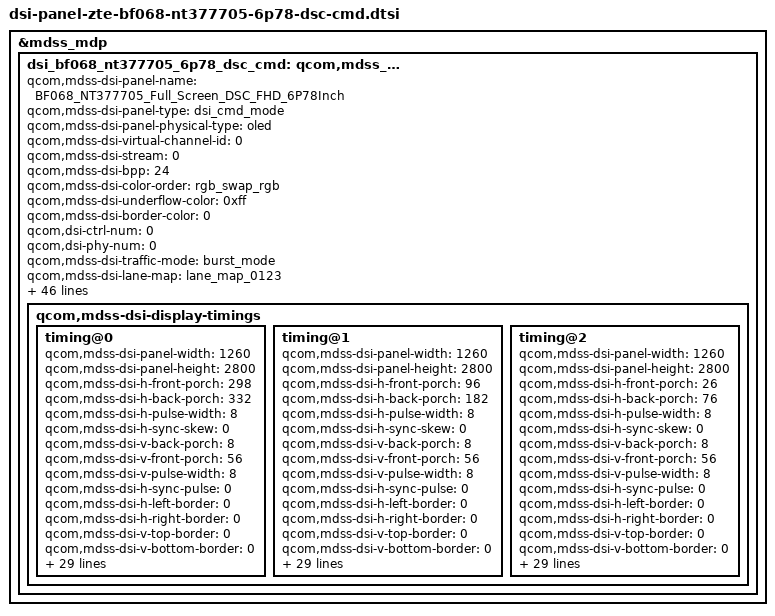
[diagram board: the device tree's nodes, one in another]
&mdss_mdp {
	dsi_bf068_nt377705_6p78_dsc_cmd: qcom,mdss_dsi_bf068_nt377705_6p78_dsc_cmd {
		qcom,mdss-dsi-panel-name =
				"BF068_NT377705_Full_Screen_DSC_FHD_6P78Inch";
		qcom,mdss-dsi-panel-type = "dsi_cmd_mode";
		qcom,mdss-dsi-panel-physical-type = "oled";
		qcom,mdss-dsi-virtual-channel-id = <0>;
		qcom,mdss-dsi-stream = <0>;
		qcom,mdss-dsi-bpp = <24>;
		qcom,mdss-dsi-color-order = "rgb_swap_rgb";
		qcom,mdss-dsi-underflow-color = <0xff>;
		qcom,mdss-dsi-border-color = <0>;
		qcom,dsi-ctrl-num = <0>;
		qcom,dsi-phy-num = <0>;
		qcom,mdss-dsi-traffic-mode = "burst_mode";
		qcom,mdss-dsi-lane-map = "lane_map_0123";
		qcom,mdss-dsi-bllp-eof-power-mode;
		qcom,mdss-dsi-bllp-power-mode;
		qcom,mdss-dsi-lane-0-state;
		qcom,mdss-dsi-lane-1-state;
		qcom,mdss-dsi-lane-2-state;
		qcom,mdss-dsi-lane-3-state;
		qcom,mdss-dsi-lp11-init;
		qcom,mdss-dsi-tx-eot-append;
		qcom,mdss-dsi-dma-trigger = "trigger_sw";
		qcom,mdss-dsi-mdp-trigger = "none";
		qcom,mdss-dsi-reset-sequence = <1 5>, <0 5>, <1 10>;
		qcom,mdss-dsi-te-pin-select = <1>;
		qcom,mdss-dsi-te-dcs-command = <1>;
		qcom,mdss-dsi-te-check-enable;
		qcom,mdss-dsi-te-using-te-pin;
		qcom,mdss-dsi-bl-min-level = <80>;
		qcom,mdss-dsi-bl-max-level = <3515>;
		qcom,mdss-dsi-bl-pmic-control-type = "bl_ctrl_dcs";
		qcom,mdss-dsi-panel-hdr-enabled;
		qcom,mdss-dsi-panel-hdr-color-primaries = <14500 15500 34015
			15980 13030 34670 6950 2565>;
		qcom,mdss-dsi-panel-peak-brightness = <6680000>;
		qcom,mdss-dsi-panel-blackness-level = <20>;
		qcom,mdss-pan-physical-width-dimension = <71>;
		qcom,mdss-pan-physical-height-dimension = <157>;
		qcom,bl-dcs-cmd-state = "dsi_lp_mode";
		qcom,mdss-dsi-display-timings {
			timing@0{
				qcom,mdss-dsi-panel-width = <1260>;
				qcom,mdss-dsi-panel-height = <2800>;
				qcom,mdss-dsi-h-front-porch = <298>;
				qcom,mdss-dsi-h-back-porch = <332>;
				qcom,mdss-dsi-h-pulse-width = <8>;
				qcom,mdss-dsi-h-sync-skew = <0>;
				qcom,mdss-dsi-v-back-porch = <8>;
				qcom,mdss-dsi-v-front-porch = <56>;
				qcom,mdss-dsi-v-pulse-width = <8>;
				qcom,mdss-dsi-h-sync-pulse = <0>;
				qcom,mdss-dsi-h-left-border = <0>;
				qcom,mdss-dsi-h-right-border = <0>;
				qcom,mdss-dsi-v-top-border = <0>;
				qcom,mdss-dsi-v-bottom-border = <0>;
				qcom,mdss-dsi-panel-framerate = <60>;
				qcom,mdss-dsi-panel-clockrate = <1093960000>;

				qcom,mdss-dsi-on-command = [
					39 01 00 00 00 00 06 F0 55 AA 52 08 00
					39 01 00 00 00 00 02 B0 0C
					39 01 00 00 00 00 02 6F 09
					39 01 00 00 00 00 04 B0 55 56 55
					39 01 00 00 00 00 04 B1 17 3B 5C
					39 01 00 00 00 00 02 6F 03
					39 01 00 00 00 00 03 B1 00 17
					39 01 00 00 00 00 02 6F 14
					39 01 00 00 00 00 03 B1 00 3B
					39 01 00 00 00 00 02 6F 16
					39 01 00 00 00 00 03 B1 00 5C
					39 01 00 00 00 00 02 6F 05
					39 01 00 00 00 00 0D B1 12 34 57 89 2C 58 84 B0 DC 08 34 60
					39 01 00 00 00 00 02 6F 21
					39 01 00 00 00 00 0F B1 00 00 24 68 AC EF 00 00 00 00 00 00 00 FF
					39 01 00 00 00 00 02 6F 18
					39 01 00 00 00 00 07 B1 02 76 04 EC 02 76
					39 01 00 00 00 00 02 6F 1E
					39 01 00 00 00 00 04 B1 0D 75 50
					39 01 00 00 00 00 02 B2 19
					39 01 00 00 00 00 02 6F 06
					39 01 00 00 00 00 07 B5 7F 4B 29 4F 00 00
					39 01 00 00 00 00 02 6F 0C
					39 01 00 00 00 00 06 B5 44 25 4F 00 00
					39 01 00 00 00 00 02 6F 11
					39 01 00 00 00 00 06 B5 29 29 29 29 29
					39 01 00 00 00 00 02 6F 18
					39 01 00 00 00 00 06 B5 00 00 00 00 00
					39 01 00 00 00 00 02 6F 1D
					39 01 00 00 00 00 06 B5 00 00 00 00 00
					39 01 00 00 00 00 02 6F 27
					39 01 00 00 00 00 06 B5 00 00 00 00 00

					39 01 00 00 00 00 06 F0 55 AA 52 08 01
					39 01 00 00 00 00 2A C3 DD 06 20 11 FF 00 06 20 11 FF 00 04 49 11 05 CC 17 04 4A 11 05 CD 17 04 4B 11 05 CF 17 04 49 11 05 CC 17 04 49 11 05 CC 17
					39 01 00 00 00 00 02 6F 05
					39 01 00 00 00 00 05 C5 15 15 15 DD
					39 01 00 00 00 00 06 F0 55 AA 52 00 00
					39 01 00 00 00 00 05 FF AA 55 A5 80
					39 01 00 00 00 00 02 6F 19
					39 01 00 00 00 00 02 F2 00
					39 01 00 00 00 00 02 6F 1A
					39 01 00 00 00 00 02 F4 55
					39 01 00 00 00 00 02 6F 2D
					39 01 00 00 00 00 02 FC 44
					39 01 00 00 00 00 02 6F 11
					39 01 00 00 00 00 03 F8 01 7B
					39 01 00 00 00 00 02 6F 2D
					39 01 00 00 00 00 03 F8 01 1D
					39 01 00 00 00 00 05 FF AA 55 A5 81
					39 01 00 00 00 00 02 6F 05
					39 01 00 00 00 00 02 FE 3C
					39 01 00 00 00 00 02 6F 02
					39 01 00 00 00 00 02 F9 04
					39 01 00 00 00 00 02 6F 1E
					39 01 00 00 00 00 02 FB 0F
					39 01 00 00 00 00 02 6F 0F
					39 01 00 00 00 00 02 F5 20
					39 01 00 00 00 00 02 6F 24
					39 01 00 00 00 00 15 FB 00 01 00 11 33 33 33 55 57 D0 00 00 44 56 77 78 9A BC DD F0

					39 01 00 00 00 00 05 FF AA 55 A5 82
					39 01 00 00 00 00 02 6F 09
					39 01 00 00 00 00 02 F2 55
					39 01 00 00 00 00 05 FF AA 55 A5 83
					39 01 00 00 00 00 02 6F 12
					39 01 00 00 00 00 02 FE 41
					39 01 00 00 00 00 02 6F 13
					39 01 00 00 00 00 02 FD 21
					39 01 00 00 00 00 05 FF AA 55 A5 00
					05 01 00 00 00 00 01 35
					39 01 00 00 00 00 02 53 20
					39 01 00 00 00 00 05 2A 00 00 04 EB
					39 01 00 00 00 00 05 2B 00 00 0A EF
					39 01 00 00 00 00 02 26 00
					39 01 00 00 00 00 03 51 0D BB
					39 01 00 00 00 00 02 6F 04
					39 01 00 00 00 00 03 51 0F FE
					39 01 00 00 00 00 03 81 01 19
					39 01 00 00 00 00 02 03 01
					39 01 00 00 00 00 03 90 03 03
					39 01 00 00 00 00 13 91 89 28 00 14 C2 00 02 3B 02 0E 00 08 05 0E 04 5C 10 F0

					39 01 00 00 00 00 06 F0 55 AA 52 08 01
					39 01 00 00 00 00 02 6F 18
					39 01 00 00 00 00 02 D8 18
					05 01 00 00 00 00 01 2C
					39 01 00 00 14 00 02 2F 02
					05 01 00 00 78 00 01 11
					05 01 00 00 00 00 01 29
					];
				qcom,mdss-dsi-off-command = [
					05 01 00 00 14 00 01 28
					05 01 00 00 78 00 01 10
				];
				qcom,mdss-dsi-on-command-state = "dsi_lp_mode";
				qcom,mdss-dsi-off-command-state = "dsi_lp_mode";

				qcom,mdss-dsi-lp1-command = [
					05 01 00 00 00 00 01 39
					05 01 00 00 00 00 01 2C
				];
				qcom,mdss-dsi-lp1-command-state =
					"dsi_lp_mode";
				qcom,mdss-dsi-nolp-command = [
					39 01 00 00 00 00 03 51 00 00
					05 01 00 00 00 00 01 38
					05 01 00 00 00 00 01 2C
				];
				qcom,mdss-dsi-nolp-command-state =
					"dsi_lp_mode";
				qcom,mdss-dsi-timing-switch-command = [
					39 01 00 00 00 00 02 2F 02
				];
				qcom,mdss-dsi-timing-switch-command-state =
					"dsi_lp_mode";
				qcom,compression-mode = "dsc";
				qcom,mdss-dsc-slice-height = <20>;
				qcom,mdss-dsc-slice-width = <630>;
				qcom,mdss-dsc-slice-per-pkt = <2>;
				qcom,mdss-dsc-bit-per-component = <8>;
				qcom,mdss-dsc-bit-per-pixel = <8>;
				qcom,mdss-dsc-block-prediction-enable;
			};
			timing@1{
				qcom,mdss-dsi-panel-width = <1260>;
				qcom,mdss-dsi-panel-height = <2800>;
				qcom,mdss-dsi-h-front-porch = <96>;
				qcom,mdss-dsi-h-back-porch = <182>;
				qcom,mdss-dsi-h-pulse-width = <8>;
				qcom,mdss-dsi-h-sync-skew = <0>;
				qcom,mdss-dsi-v-back-porch = <8>;
				qcom,mdss-dsi-v-front-porch = <56>;
				qcom,mdss-dsi-v-pulse-width = <8>;
				qcom,mdss-dsi-h-sync-pulse = <0>;
				qcom,mdss-dsi-h-left-border = <0>;
				qcom,mdss-dsi-h-right-border = <0>;
				qcom,mdss-dsi-v-top-border = <0>;
				qcom,mdss-dsi-v-bottom-border = <0>;
				qcom,mdss-dsi-panel-framerate = <90>;
				qcom,mdss-dsi-panel-clockrate = <1094960000>;

				qcom,mdss-dsi-on-command = [
					39 01 00 00 00 00 06 F0 55 AA 52 08 00
					39 01 00 00 00 00 02 B0 0C
					39 01 00 00 00 00 02 6F 09
					39 01 00 00 00 00 04 B0 55 56 55
					39 01 00 00 00 00 04 B1 17 3B 5C
					39 01 00 00 00 00 02 6F 03
					39 01 00 00 00 00 03 B1 00 17
					39 01 00 00 00 00 02 6F 14
					39 01 00 00 00 00 03 B1 00 3B
					39 01 00 00 00 00 02 6F 16
					39 01 00 00 00 00 03 B1 00 5C
					39 01 00 00 00 00 02 6F 05
					39 01 00 00 00 00 0D B1 12 34 57 89 2C 58 84 B0 DC 08 34 60
					39 01 00 00 00 00 02 6F 21
					39 01 00 00 00 00 0F B1 00 00 24 68 AC EF 00 00 00 00 00 00 00 FF
					39 01 00 00 00 00 02 6F 18
					39 01 00 00 00 00 07 B1 02 76 04 EC 02 76
					39 01 00 00 00 00 02 6F 1E
					39 01 00 00 00 00 04 B1 0D 75 50
					39 01 00 00 00 00 02 B2 19
					39 01 00 00 00 00 02 6F 06
					39 01 00 00 00 00 07 B5 7F 4B 29 4F 00 00
					39 01 00 00 00 00 02 6F 0C
					39 01 00 00 00 00 06 B5 44 25 4F 00 00
					39 01 00 00 00 00 02 6F 11
					39 01 00 00 00 00 06 B5 29 29 29 29 29
					39 01 00 00 00 00 02 6F 18
					39 01 00 00 00 00 06 B5 00 00 00 00 00
					39 01 00 00 00 00 02 6F 1D
					39 01 00 00 00 00 06 B5 00 00 00 00 00
					39 01 00 00 00 00 02 6F 27
					39 01 00 00 00 00 06 B5 00 00 00 00 00

					39 01 00 00 00 00 06 F0 55 AA 52 08 01
					39 01 00 00 00 00 2A C3 DD 06 20 11 FF 00 06 20 11 FF 00 04 49 11 05 CC 17 04 4A 11 05 CD 17 04 4B 11 05 CF 17 04 49 11 05 CC 17 04 49 11 05 CC 17
					39 01 00 00 00 00 02 6F 05
					39 01 00 00 00 00 05 C5 15 15 15 DD
					39 01 00 00 00 00 06 F0 55 AA 52 00 00
					39 01 00 00 00 00 05 FF AA 55 A5 80
					39 01 00 00 00 00 02 6F 19
					39 01 00 00 00 00 02 F2 00
					39 01 00 00 00 00 02 6F 1A
					39 01 00 00 00 00 02 F4 55
					39 01 00 00 00 00 02 6F 2D
					39 01 00 00 00 00 02 FC 44
					39 01 00 00 00 00 02 6F 11
					39 01 00 00 00 00 03 F8 01 7B
					39 01 00 00 00 00 02 6F 2D
					39 01 00 00 00 00 03 F8 01 1D
					39 01 00 00 00 00 05 FF AA 55 A5 81
					39 01 00 00 00 00 02 6F 05
					39 01 00 00 00 00 02 FE 3C
					39 01 00 00 00 00 02 6F 02
					39 01 00 00 00 00 02 F9 04
					39 01 00 00 00 00 02 6F 1E
					39 01 00 00 00 00 02 FB 0F
					39 01 00 00 00 00 02 6F 0F
					39 01 00 00 00 00 02 F5 20
					39 01 00 00 00 00 02 6F 24
					39 01 00 00 00 00 15 FB 00 01 00 11 33 33 33 55 57 D0 00 00 44 56 77 78 9A BC DD F0

					39 01 00 00 00 00 05 FF AA 55 A5 82
					39 01 00 00 00 00 02 6F 09
					39 01 00 00 00 00 02 F2 55
					39 01 00 00 00 00 05 FF AA 55 A5 83
					39 01 00 00 00 00 02 6F 12
					39 01 00 00 00 00 02 FE 41
					39 01 00 00 00 00 02 6F 13
					39 01 00 00 00 00 02 FD 21
					39 01 00 00 00 00 05 FF AA 55 A5 00
					05 01 00 00 00 00 01 35
					39 01 00 00 00 00 02 53 20
					39 01 00 00 00 00 05 2A 00 00 04 EB
					39 01 00 00 00 00 05 2B 00 00 0A EF
					39 01 00 00 00 00 02 26 00
					39 01 00 00 00 00 03 51 0D BB
					39 01 00 00 00 00 02 6F 04
					39 01 00 00 00 00 03 51 0F FE
					39 01 00 00 00 00 03 81 01 19
					39 01 00 00 00 00 02 03 01
					39 01 00 00 00 00 03 90 03 03
					39 01 00 00 00 00 13 91 89 28 00 14 C2 00 02 3B 02 0E 00 08 05 0E 04 5C 10 F0

					39 01 00 00 00 00 06 F0 55 AA 52 08 01
					39 01 00 00 00 00 02 6F 18
					39 01 00 00 00 00 02 D8 18
					05 01 00 00 00 00 01 2C
					39 01 00 00 14 00 02 2F 01
					05 01 00 00 78 00 01 11
					05 01 00 00 00 00 01 29
					];
				qcom,mdss-dsi-off-command = [
					05 01 00 00 14 00 01 28
					05 01 00 00 78 00 01 10
				];
				qcom,mdss-dsi-on-command-state = "dsi_lp_mode";
				qcom,mdss-dsi-off-command-state = "dsi_lp_mode";

				qcom,mdss-dsi-lp1-command = [
					05 01 00 00 00 00 01 39
					05 01 00 00 00 00 01 2C
				];
				qcom,mdss-dsi-lp1-command-state =
					"dsi_lp_mode";
				qcom,mdss-dsi-nolp-command = [
					39 01 00 00 00 00 03 51 00 00
					05 01 00 00 00 00 01 38
					05 01 00 00 00 00 01 2C
				];
				qcom,mdss-dsi-timing-switch-command = [
					39 01 00 00 00 00 02 2F 01
				];
				qcom,mdss-dsi-timing-switch-command-state =
					"dsi_lp_mode";
				qcom,mdss-dsi-nolp-command-state =
					"dsi_lp_mode";
				qcom,compression-mode = "dsc";
				qcom,mdss-dsc-slice-height = <20>;
				qcom,mdss-dsc-slice-width = <630>;
				qcom,mdss-dsc-slice-per-pkt = <2>;
				qcom,mdss-dsc-bit-per-component = <8>;
				qcom,mdss-dsc-bit-per-pixel = <8>;
				qcom,mdss-dsc-block-prediction-enable;
			};
			timing@2{
				qcom,mdss-dsi-panel-width = <1260>;
				qcom,mdss-dsi-panel-height = <2800>;
				qcom,mdss-dsi-h-front-porch = <26>;
				qcom,mdss-dsi-h-back-porch = <76>;
				qcom,mdss-dsi-h-pulse-width = <8>;
				qcom,mdss-dsi-h-sync-skew = <0>;
				qcom,mdss-dsi-v-back-porch = <8>;
				qcom,mdss-dsi-v-front-porch = <56>;
				qcom,mdss-dsi-v-pulse-width = <8>;
				qcom,mdss-dsi-h-sync-pulse = <0>;
				qcom,mdss-dsi-h-left-border = <0>;
				qcom,mdss-dsi-h-right-border = <0>;
				qcom,mdss-dsi-v-top-border = <0>;
				qcom,mdss-dsi-v-bottom-border = <0>;
				qcom,mdss-dsi-panel-framerate = <120>;
				qcom,mdss-dsi-panel-clockrate = <1095960000>;

				qcom,mdss-dsi-on-command = [
					39 01 00 00 00 00 06 F0 55 AA 52 08 00
					39 01 00 00 00 00 02 B0 0C
					39 01 00 00 00 00 02 6F 09
					39 01 00 00 00 00 04 B0 55 56 55
					39 01 00 00 00 00 04 B1 17 3B 5C
					39 01 00 00 00 00 02 6F 03
					39 01 00 00 00 00 03 B1 00 17
					39 01 00 00 00 00 02 6F 14
					39 01 00 00 00 00 03 B1 00 3B
					39 01 00 00 00 00 02 6F 16
					39 01 00 00 00 00 03 B1 00 5C
					39 01 00 00 00 00 02 6F 05
					39 01 00 00 00 00 0D B1 12 34 57 89 2C 58 84 B0 DC 08 34 60
					39 01 00 00 00 00 02 6F 21
					39 01 00 00 00 00 0F B1 00 00 24 68 AC EF 00 00 00 00 00 00 00 FF
					39 01 00 00 00 00 02 6F 18
					39 01 00 00 00 00 07 B1 02 76 04 EC 02 76
					39 01 00 00 00 00 02 6F 1E
					39 01 00 00 00 00 04 B1 0D 75 50
					39 01 00 00 00 00 02 B2 19
					39 01 00 00 00 00 02 6F 06
					39 01 00 00 00 00 07 B5 7F 4B 29 4F 00 00
					39 01 00 00 00 00 02 6F 0C
					39 01 00 00 00 00 06 B5 44 25 4F 00 00
					39 01 00 00 00 00 02 6F 11
					39 01 00 00 00 00 06 B5 29 29 29 29 29
					39 01 00 00 00 00 02 6F 18
					39 01 00 00 00 00 06 B5 00 00 00 00 00
					39 01 00 00 00 00 02 6F 1D
					39 01 00 00 00 00 06 B5 00 00 00 00 00
					39 01 00 00 00 00 02 6F 27
					39 01 00 00 00 00 06 B5 00 00 00 00 00

					39 01 00 00 00 00 06 F0 55 AA 52 08 01
					39 01 00 00 00 00 2A C3 DD 06 20 11 FF 00 06 20 11 FF 00 04 49 11 05 CC 17 04 4A 11 05 CD 17 04 4B 11 05 CF 17 04 49 11 05 CC 17 04 49 11 05 CC 17
					39 01 00 00 00 00 02 6F 05
					39 01 00 00 00 00 05 C5 15 15 15 DD
					39 01 00 00 00 00 06 F0 55 AA 52 00 00
					39 01 00 00 00 00 05 FF AA 55 A5 80
					39 01 00 00 00 00 02 6F 19
					39 01 00 00 00 00 02 F2 00
					39 01 00 00 00 00 02 6F 1A
					39 01 00 00 00 00 02 F4 55
					39 01 00 00 00 00 02 6F 2D
					39 01 00 00 00 00 02 FC 44
					39 01 00 00 00 00 02 6F 11
					39 01 00 00 00 00 03 F8 01 7B
					39 01 00 00 00 00 02 6F 2D
					39 01 00 00 00 00 03 F8 01 1D
					39 01 00 00 00 00 05 FF AA 55 A5 81
					39 01 00 00 00 00 02 6F 05
					39 01 00 00 00 00 02 FE 3C
					39 01 00 00 00 00 02 6F 02
					39 01 00 00 00 00 02 F9 04
					39 01 00 00 00 00 02 6F 1E
					39 01 00 00 00 00 02 FB 0F
					39 01 00 00 00 00 02 6F 0F
					39 01 00 00 00 00 02 F5 20
					39 01 00 00 00 00 02 6F 24
					39 01 00 00 00 00 15 FB 00 01 00 11 33 33 33 55 57 D0 00 00 44 56 77 78 9A BC DD F0

					39 01 00 00 00 00 05 FF AA 55 A5 82
					39 01 00 00 00 00 02 6F 09
					39 01 00 00 00 00 02 F2 55
					39 01 00 00 00 00 05 FF AA 55 A5 83
					39 01 00 00 00 00 02 6F 12
					39 01 00 00 00 00 02 FE 41
					39 01 00 00 00 00 02 6F 13
					39 01 00 00 00 00 02 FD 21
					39 01 00 00 00 00 05 FF AA 55 A5 00
					05 01 00 00 00 00 01 35
					39 01 00 00 00 00 02 53 20
					39 01 00 00 00 00 05 2A 00 00 04 EB
					39 01 00 00 00 00 05 2B 00 00 0A EF
					39 01 00 00 00 00 02 26 00
					39 01 00 00 00 00 03 51 0D BB
					39 01 00 00 00 00 02 6F 04
					39 01 00 00 00 00 03 51 0F FE
					39 01 00 00 00 00 03 81 01 19
					39 01 00 00 00 00 02 03 01
					39 01 00 00 00 00 03 90 03 03
					39 01 00 00 00 00 13 91 89 28 00 14 C2 00 02 3B 02 0E 00 08 05 0E 04 5C 10 F0

					39 01 00 00 00 00 06 F0 55 AA 52 08 01
					39 01 00 00 00 00 02 6F 18
					39 01 00 00 00 00 02 D8 18
					05 01 00 00 00 00 01 2C
					39 01 00 00 14 00 02 2F 00
					05 01 00 00 78 00 01 11
					05 01 00 00 00 00 01 29
					];
				qcom,mdss-dsi-off-command = [
					05 01 00 00 14 00 01 28
					05 01 00 00 78 00 01 10
				];
				qcom,mdss-dsi-on-command-state = "dsi_lp_mode";
				qcom,mdss-dsi-off-command-state = "dsi_lp_mode";

				qcom,mdss-dsi-lp1-command = [
					05 01 00 00 00 00 01 39
					05 01 00 00 00 00 01 2C
				];
				qcom,mdss-dsi-lp1-command-state =
					"dsi_lp_mode";
				qcom,mdss-dsi-nolp-command = [
					39 01 00 00 00 00 03 51 00 00
					05 01 00 00 00 00 01 38
					05 01 00 00 00 00 01 2C
				];
				qcom,mdss-dsi-timing-switch-command = [
					39 01 00 00 00 00 02 2F 00
				];
				qcom,mdss-dsi-timing-switch-command-state =
					"dsi_lp_mode";
				qcom,mdss-dsi-nolp-command-state =
					"dsi_lp_mode";
				qcom,compression-mode = "dsc";
				qcom,mdss-dsc-slice-height = <20>;
				qcom,mdss-dsc-slice-width = <630>;
				qcom,mdss-dsc-slice-per-pkt = <2>;
				qcom,mdss-dsc-bit-per-component = <8>;
				qcom,mdss-dsc-bit-per-pixel = <8>;
				qcom,mdss-dsc-block-prediction-enable;
			};
		};
	};
};

/* panel feature */
&dsi_bf068_nt377705_6p78_dsc_cmd {
    /* zte disp feature */
	zte,hbm_enabled;
	zte,hdr_enabled;
	zte,fps_enabled;
	zte,acl_enabled;
	zte,aod_enabled;
	zte,hdr_brightness = <0xFFF>;
	zte,hdr_threshold = <0xE80>;
	zte,hdr_sunlight_bl_ctrl;
	zte,aod-exit-delay-time = <150>;
	zte,color_space_enabled;
	zte,hbm_need_delay;
	qcom,mdss-dsi-display-timings {
		timing@0 {
		   #include "dsi-panel-zte-bf068-nt377705-common.dtsi"
		};
		timing@1 {
		   #include "dsi-panel-zte-bf068-nt377705-common.dtsi"
		};
		timing@2 {
		   #include "dsi-panel-zte-bf068-nt377705-common.dtsi"
		};
	};
};

/* zte dsip power supply */
&dsi_bf068_nt377705_6p78_dsc_cmd {
	qcom,panel-supply-entries = <&dsi_panel_pwr_supply_z50s1>;
	qcom,mdss-dsi-bl-pmic-control-type = "bl_ctrl_dcs";
	qcom,mdss-brightness-max-level = <2047>;
	qcom,mdss-dsi-bl-inverted-dbv;
	qcom,platform-reset-gpio = <&tlmm 133 0>;
	qcom,ulps-enabled;
	qcom,dsi-select-clocks = "pll_byte_clk0", "pll_dsi_clk0";
	qcom,mdss-dsi-display-timings {
		timing@0 {
			/* DPHY regular margins */
			qcom,mdss-dsi-panel-phy-timings = [00 24 09 0A 1A 25 09
				0A 09 02 04 00 1E 0F];
			qcom,display-topology = <2 2 1>;
			qcom,default-topology-index = <0>;
		};
		timing@1 {
			/* DPHY regular margins */
			qcom,mdss-dsi-panel-phy-timings = [00 25 09 0A 1A 25 09
				0A 09 02 04 00 1E 0F];
			qcom,display-topology = <2 2 1>;
			qcom,default-topology-index = <0>;
		};
		timing@2 {
			/* DPHY regular margins */
			qcom,mdss-dsi-panel-phy-timings = [00 24 0A 0A 1A 25 09
				0A 09 02 04 00 1E 0F];
			qcom,display-topology = <2 2 1>;
			qcom,default-topology-index = <0>;
		};
	};
};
